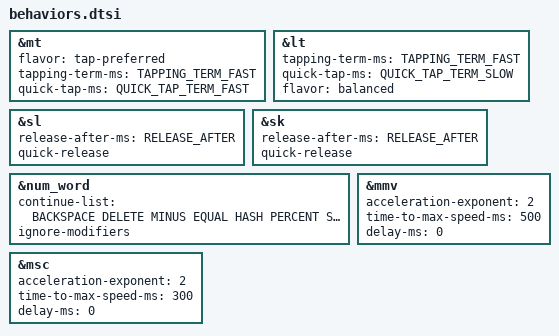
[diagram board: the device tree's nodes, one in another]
#define QUICK_TAP_TERM_SLOW  220
#define QUICK_TAP_TERM_FAST  175

#define TAPPING_TERM_SLOW    280
#define TAPPING_TERM_MEDIUM  220
#define TAPPING_TERM_FAST    175

#define PRIOR_IDLE_TERM      150

#define RELEASE_AFTER        1000

#define ZMK_MOUSE_DEFAULT_MOVE_VAL 600
#define ZMK_MOUSE_DEFAULT_SCRL_VAL 20


&mt {
    flavor = "tap-preferred";
    tapping-term-ms = <TAPPING_TERM_FAST>;
    quick-tap-ms = <QUICK_TAP_TERM_FAST>;
};

&lt {
    tapping-term-ms = <TAPPING_TERM_FAST>;
    quick-tap-ms = <QUICK_TAP_TERM_SLOW>;
    flavor = "balanced";
};

&sl {
    release-after-ms = <RELEASE_AFTER>;
    quick-release;
};

&sk {
    release-after-ms = <RELEASE_AFTER>;
    quick-release;
};

&num_word {
    continue-list = <
        BACKSPACE DELETE
        MINUS EQUAL HASH PERCENT STAR KP_DIVIDE PLUS
        KP_N0 KP_N1 KP_N2 KP_N3 KP_N4 KP_N5 KP_N6 KP_N7 KP_N8 KP_N9
    >;
    ignore-modifiers;
};

&mmv {
    acceleration-exponent = <2>;
    time-to-max-speed-ms = <500>;
    delay-ms = <0>;
};

&msc {
    acceleration-exponent = <2>;
    time-to-max-speed-ms = <300>;
    delay-ms = <0>;
};

